# K1921VK01T register map
Vendor: NIIET; Series: K1921VKx; File version: 2.2
CPU: CM4 r0p1, little endian, MPU, FPU, 3 interrupt priority bits
Registers are 32-bit, read-write, reset 0x0 unless marked. A register's access mark holds for its fields unless they carry their own. Offsets are from the block's base; [hi:lo] are bit positions; lines under a group give offsets from that group; {n}, {i} and the like mark numbered series; 'fields as' and 'values as' point back to an identical list.

## NT_ADC — ADC controller registers
Base 0x80000000
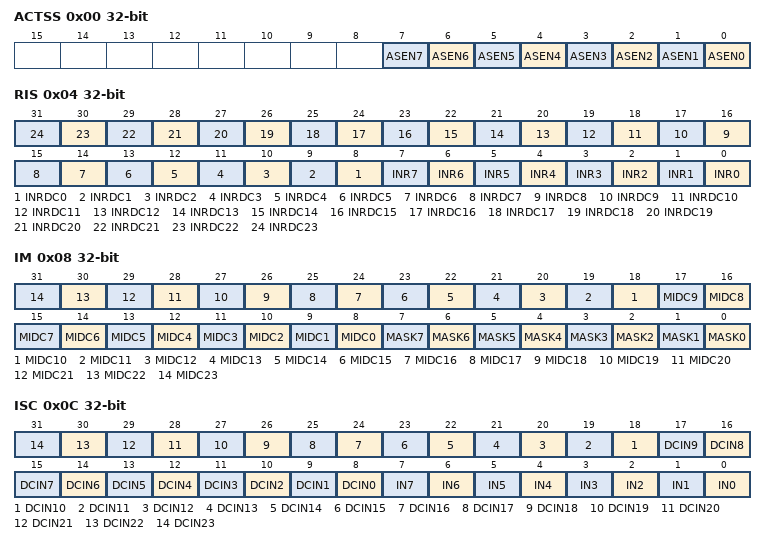
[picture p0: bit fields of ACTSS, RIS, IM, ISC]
0x00 ACTSS — Enable sequencer register
  [n] ASEN{n} (n=0..7) — Enable sequencer {n}
0x04 RIS ro — Raw interrupt status register
  [n+8] INRDC{n} (n=0..23) — DCMP {n} raw interrupt status
  [n] INR{n} (n=0..7) — Sequencer {n} raw interrupt status
0x08 IM — Interrupt mask register
  [n+8] MIDC{n} (n=0..23) — DCMP {n} interrupt mask
  [n] MASK{n} (n=0..7) — Sequencer {n} interrupt mask
0x0C ISC — Interrupt status and clear register
  [n+8] DCIN{n} (n=0..23) — DCMP {n} masked interrupt status / Write 1 to clear (also clear raw status)
  [n] IN{n} (n=0..7) — Sequencer {n} masked interrupt status / Write 1 to clear (also clear raw status)
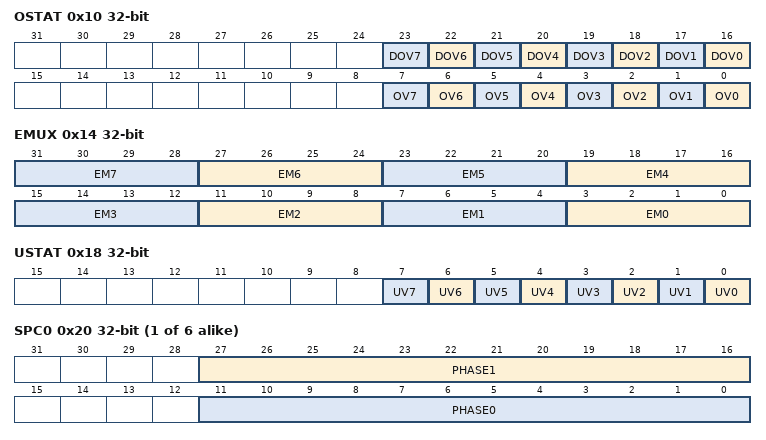
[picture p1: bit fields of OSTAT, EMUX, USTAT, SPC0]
0x10 OSTAT — FIFO overflow status register
  [n+16] DOV{n} (n=0..7) — Sequencer {n} FIFO DMA request overflow
  [n] OV{n} (n=0..7) — Sequencer {n} FIFO overflow
0x14 EMUX — Sequencer start event selection register
  [all] fields
    0=SwReq (software request by GSYNC bit); 1=CMP0 (Analog comparator 0 request); 2=CMP1 (Analog comparator 1 request); 3=CMP2 (Analog comparator 2 request); 4=ITGPIO (Any GPIO interrupt); 5=TIMER (Timer request); {v}=PWM{v-6} (PWM {v-6} request) (v=6..11); 15=Cycle mode
  [4n+3:4n] EM{n} (n=0..7) — Select start event for sequencer {n}
0x18 USTAT — FIFO underflow status register
  [n] UV{n} (n=0..7) — Sequencer {n} FIFO underflow
{0x20+4i} SPC{i} (i=0..5) — ADC{2i}, ADC{2i+1} start delay register
  [27:16] PHASE{2i+1} — ADC{2i+1} start delay (channel {4i+2},{4i+3})
  [11:0] PHASE{2i} — ADC{2i} start delay (channel {4i},{4i+1})
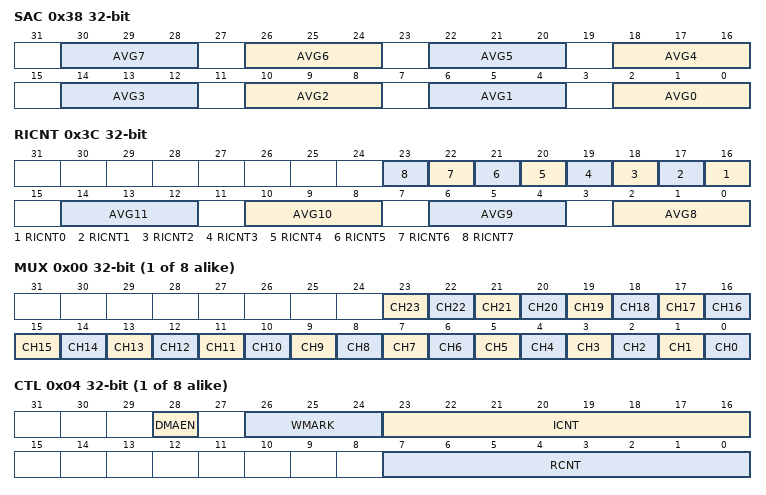
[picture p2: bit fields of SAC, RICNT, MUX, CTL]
0x38 SAC — Average control (ADC0-7) register
  [all] fields
    0=Disable (Average disabled); 1=Average2 (Average with 2 measures); 2=Average4 (Average with 4 measures); 3=Average8 (Average with 8 measures); 4=Average16 (Average with 16 measures); 5=Average32 (Average with 32 measures); 6=Average64 (Average with 64 measures)
  [4n+2:4n] AVG{n} (n=0..7) — ADC{n} average control
0x3C RICNT — Interrupt counter reset control / Average control (ADC8-11) register
  [n+16] RICNT{n} (n=0..7) — Disable interrupt counter reset on sequencer {n} start
  [4n-30:4n-32] AVG{n} (n=8..11) — ADC{n} average control
    values as the fields of SAC
{0x40+0x20*i} SEQ[{i}] (i=0..7) group
  0x00 MUX — Sequencer ADC channels selection register
    [23] CH23 — Enable measure on channnel 23 (ADC11 B)
    [22] CH22 — Enable measure on channnel 22 (ADC11 A)
    [21] CH21 — Enable measure on channnel 21 (ADC10 B)
    [20] CH20 — Enable measure on channnel 20 (ADC10 A)
    [19] CH19 — Enable measure on channnel 19 (ADC9 B)
    [18] CH18 — Enable measure on channnel 18 (ADC9 A)
    [17] CH17 — Enable measure on channnel 17 (ADC8 B)
    [16] CH16 — Enable measure on channnel 16 (ADC8 A)
    [15] CH15 — Enable measure on channnel 15 (ADC7 B)
    [14] CH14 — Enable measure on channnel 14 (ADC7 A)
    [13] CH13 — Enable measure on channnel 13 (ADC6 B)
    [12] CH12 — Enable measure on channnel 12 (ADC6 A)
    [11] CH11 — Enable measure on channnel 11 (ADC5 B)
    [10] CH10 — Enable measure on channnel 10 (ADC5 A)
    [9] CH9 — Enable measure on channnel 9 (ADC4 B)
    [8] CH8 — Enable measure on channnel 8 (ADC4 A)
    [7] CH7 — Enable measure on channnel 7 (ADC3 B)
    [6] CH6 — Enable measure on channnel 6 (ADC3 A)
    [5] CH5 — Enable measure on channnel 5 (ADC2 B)
    [4] CH4 — Enable measure on channnel 4 (ADC2 A)
    [3] CH3 — Enable measure on channnel 3 (ADC1 B)
    [2] CH2 — Enable measure on channnel 2 (ADC1 A)
    [1] CH1 — Enable measure on channnel 1 (ADC0 B)
    [0] CH0 — Enable measure on channnel 0 (ADC0 A)
  0x04 CTL — Sequencer control register
    [28] DMAEN — Enable DMA use
    [26:24] WMARK — FIFO load threshold for DMA request generation
      1=Level1 (1 measure for dma request); 2=Level2 (2 measures for dma request); 3=Level4 (4 measures for dma request); 4=Level8 (8 measures for dma request); 5=Level16 (16 measures for dma request); 6=Level32 (32 measures for dma request)
    [23:16] ICNT — Number of ADC restarts for interrupt generation
    [7:0] RCNT — Number of ADC restarts by seqensor
  0x0C FSTAT ro — Sequencer FIFO load status register
    [5:0] FLOAD — Sequencer FIFO current load value
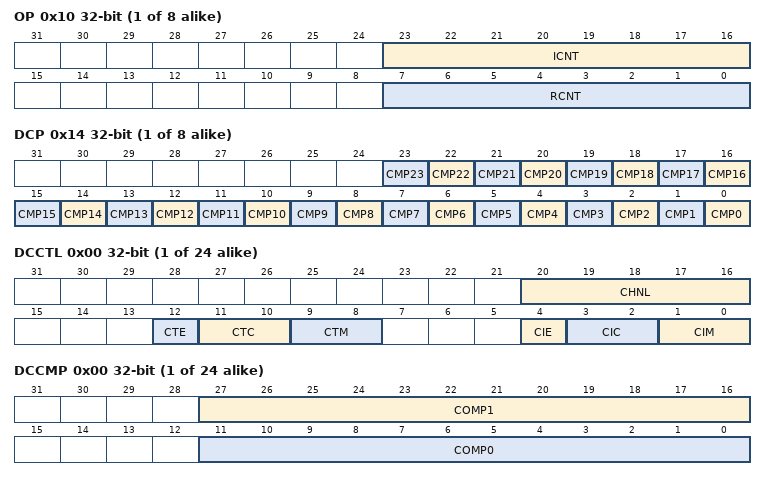
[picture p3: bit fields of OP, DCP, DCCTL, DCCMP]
  0x10 OP — Sequencer ADC restart counter register
    [23:16] ICNT — Current number of ADC restarts for interrupt generation
    [7:0] RCNT ro — Current number of ADC restarts by seqensor
  0x14 DCP — Sequencer digital comparator selection register
    [n] CMP{n} (n=0..23) — Enable DCMP {n}
  0x18 TMR — Sequencer ADC restart timer register
    [23:0] TMR — Sequencer ADC restart timer value
  0x1C FIFO ro — Sequencer FIFO register
    [15:0] DATA — AD conversion value
{0x140+4i} DCCTL[{i}] (i=0..23) group
  0x00 DCCTL — Digital comparator control register
    [20:16] CHNL — ADC channel selection
    [12] CTE — Enable DCMP output trigger
    [11:10] CTC — DCMP output trigger compare conditions
      0=Low (result lower or equal COMP0); 1=Window (result between COMP0 and COMP1 or equal any of them); 3=High (result higher or equal COMP1)
    [9:8] CTM — DCMP output trigger mode
      0=multiple trigger mode; 1=single trigger mode; 2=MultipleHyst (multiple trigger mode with hysteresis); 3=SingleHyst (single trigger mode with hysteresis)
    [4] CIE — Enable DCMP interrupt generation
    [3:2] CIC — DCMP interrupt generation compare conditions
      values as CTC
    [1:0] CIM — DCMP interrupt generation mode
      values as CTM
{0x1A0+4i} DCCMP[{i}] (i=0..23) group
  0x00 DCCMP — Digital comparator range register
    [27:16] COMP1 — High threshold compare value
    [11:0] COMP0 — Low threshold compare value
{0x200+4i} DCVAL[{i}] (i=0..23) group
  0x00 DCVAL ro — Digital comparator measure value register
    [11:0] VAL — Value of last compared AD conversion result
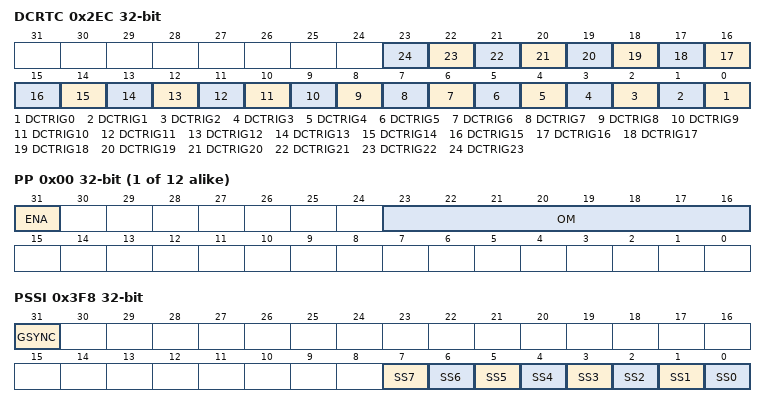
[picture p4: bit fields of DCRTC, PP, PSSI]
0x2EC DCRTC wo — Digital comparator output trigger status register
  [n] DCTRIG{n} (n=0..23) — DCMP {n} output trigger status
{0x300+4i} PP[{i}] (i=0..11) group
  0x00 PP — ADC control register
    [31] ENA — Enable ADC
    [23:16] OM — ADC mode
0x3F8 PSSI — Sequencer sync register
  [31] GSYNC — Sync all sequencers
  [n] SS{n} wo (n=0..7) — Enable sequencer {n} software sync
